AUTOSAR XML (schema 00046)
package /ComponentTypes
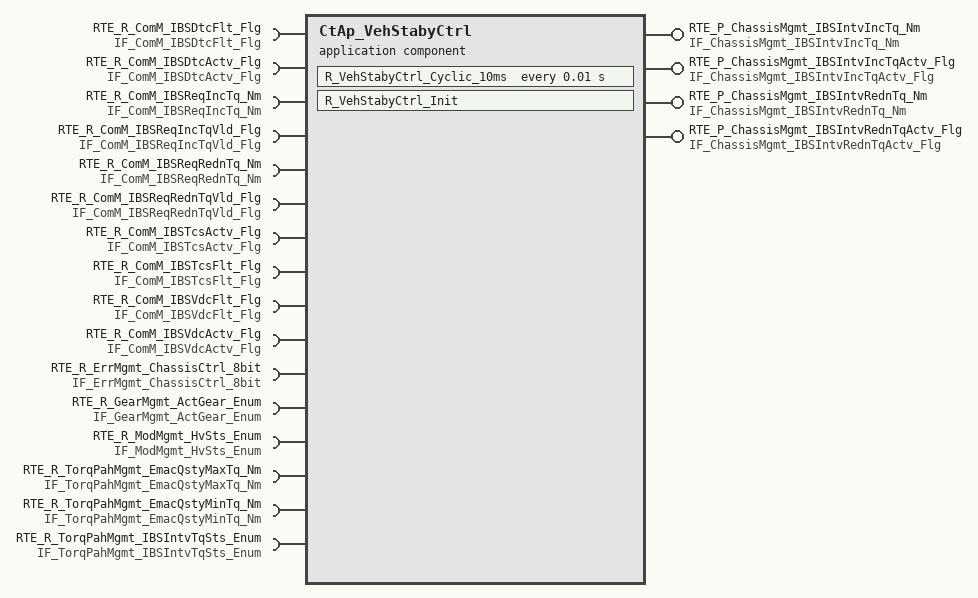
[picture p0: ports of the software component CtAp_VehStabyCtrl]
  application sw component type CtAp_VehStabyCtrl
    4 x provide port:
      RTE_P_ChassisMgmt_IBSIntvIncTq_Nm: nonqueued-sender-com-spec{data-element=tec_ChassisMgmt_IBSIntvIncTq_Nm, init-value=0}, provided-interface=IF_ChassisMgmt_IBSIntvIncTq_Nm
      RTE_P_ChassisMgmt_IBSIntvIncTqActv_Flg: nonqueued-sender-com-spec{data-element=tec_ChassisMgmt_IBSIntvIncTqActv_Flg, init-value=0}, provided-interface=IF_ChassisMgmt_IBSIntvIncTqActv_Flg
      RTE_P_ChassisMgmt_IBSIntvRednTq_Nm: nonqueued-sender-com-spec{data-element=tec_ChassisMgmt_IBSIntvRednTq_Nm, init-value=0}, provided-interface=IF_ChassisMgmt_IBSIntvRednTq_Nm
      RTE_P_ChassisMgmt_IBSIntvRednTqActv_Flg: nonqueued-sender-com-spec{data-element=tec_ChassisMgmt_IBSIntvRednTqActv_Flg, init-value=0}, provided-interface=IF_ChassisMgmt_IBSIntvRednTqActv_Flg
    16 x require port:
      RTE_R_ComM_IBSDtcFlt_Flg: nonqueued-receiver-com-spec{data-element=tec_ComM_IBSDtcFlt_Flg, filter=data-filter-type=ALWAYS, init-value=0}, required-interface=IF_ComM_IBSDtcFlt_Flg
      RTE_R_ComM_IBSDtcActv_Flg: nonqueued-receiver-com-spec{data-element=tec_ComM_IBSDtcActv_Flg, filter=data-filter-type=ALWAYS, init-value=0}, required-interface=IF_ComM_IBSDtcActv_Flg
      RTE_R_ComM_IBSReqIncTq_Nm: nonqueued-receiver-com-spec{data-element=tec_ComM_IBSReqIncTq_Nm, filter=data-filter-type=ALWAYS, init-value=0}, required-interface=IF_ComM_IBSReqIncTq_Nm
      RTE_R_ComM_IBSReqIncTqVld_Flg: nonqueued-receiver-com-spec{data-element=tec_ComM_IBSReqIncTqVld_Flg, filter=data-filter-type=ALWAYS, init-value=0}, required-interface=IF_ComM_IBSReqIncTqVld_Flg
      RTE_R_ComM_IBSReqRednTq_Nm: nonqueued-receiver-com-spec{data-element=tec_ComM_IBSReqRednTq_Nm, filter=data-filter-type=ALWAYS, init-value=0}, required-interface=IF_ComM_IBSReqRednTq_Nm
      RTE_R_ComM_IBSReqRednTqVld_Flg: nonqueued-receiver-com-spec{data-element=tec_ComM_IBSReqRednTqVld_Flg, filter=data-filter-type=ALWAYS, init-value=0}, required-interface=IF_ComM_IBSReqRednTqVld_Flg
      RTE_R_ComM_IBSTcsActv_Flg: nonqueued-receiver-com-spec{data-element=tec_ComM_IBSTcsActv_Flg, filter=data-filter-type=ALWAYS, init-value=0}, required-interface=IF_ComM_IBSTcsActv_Flg
      RTE_R_ComM_IBSTcsFlt_Flg: nonqueued-receiver-com-spec{data-element=tec_ComM_IBSTcsFlt_Flg, filter=data-filter-type=ALWAYS, init-value=0}, required-interface=IF_ComM_IBSTcsFlt_Flg
      RTE_R_ComM_IBSVdcFlt_Flg: nonqueued-receiver-com-spec{data-element=tec_ComM_IBSVdcFlt_Flg, filter=data-filter-type=ALWAYS, init-value=0}, required-interface=IF_ComM_IBSVdcFlt_Flg
      RTE_R_ComM_IBSVdcActv_Flg: nonqueued-receiver-com-spec{data-element=tec_ComM_IBSVdcActv_Flg, filter=data-filter-type=ALWAYS, init-value=0}, required-interface=IF_ComM_IBSVdcActv_Flg
      RTE_R_ErrMgmt_ChassisCtrl_8bit: nonqueued-receiver-com-spec{data-element=tec_ErrMgmt_ChassisCtrl_8bit, filter=data-filter-type=ALWAYS, init-value=0}, required-interface=IF_ErrMgmt_ChassisCtrl_8bit
      RTE_R_GearMgmt_ActGear_Enum: nonqueued-receiver-com-spec{data-element=tec_GearMgmt_ActGear_Enum, filter=data-filter-type=ALWAYS, init-value=0}, required-interface=IF_GearMgmt_ActGear_Enum
      RTE_R_ModMgmt_HvSts_Enum: nonqueued-receiver-com-spec{data-element=tec_ModMgmt_HvSts_Enum, filter=data-filter-type=ALWAYS, init-value=0}, required-interface=IF_ModMgmt_HvSts_Enum
      RTE_R_TorqPahMgmt_EmacQstyMaxTq_Nm: nonqueued-receiver-com-spec{data-element=tec_TorqPahMgmt_EmacQstyMaxTq_Nm, filter=data-filter-type=ALWAYS, init-value=0}, required-interface=IF_TorqPahMgmt_EmacQstyMaxTq_Nm
      RTE_R_TorqPahMgmt_EmacQstyMinTq_Nm: nonqueued-receiver-com-spec{data-element=tec_TorqPahMgmt_EmacQstyMinTq_Nm, filter=data-filter-type=ALWAYS, init-value=0}, required-interface=IF_TorqPahMgmt_EmacQstyMinTq_Nm
      RTE_R_TorqPahMgmt_IBSIntvTqSts_Enum: nonqueued-receiver-com-spec{data-element=tec_TorqPahMgmt_IBSIntvTqSts_Enum, filter=data-filter-type=ALWAYS, init-value=0}, required-interface=IF_TorqPahMgmt_IBSIntvTqSts_Enum
    behavior CtAp_VehStabyCtrl_InternalBehavior
      init event CtAp_VehStabyCtrl_InitEvent: start-on-event=R_VehStabyCtrl_Init
      timing event TMT_R_VehStabyCtrl_Cyclic_10ms: start-on-event=R_VehStabyCtrl_Cyclic_10ms, period=0.01
      runnable R_VehStabyCtrl_Init
      runnable R_VehStabyCtrl_Cyclic_10ms
        data-receive-point-by-arguments:
          16 x access:
            REC_RTE_R_ComM_IBSDtcActv_Flg_tec_ComM_IBSDtcActv_Flg: accessed-variable=RTE_R_ComM_IBSDtcActv_Flg.tec_ComM_IBSDtcActv_Flg
            REC_RTE_R_ComM_IBSDtcFlt_Flg_tec_ComM_IBSDtcFlt_Flg: accessed-variable=RTE_R_ComM_IBSDtcFlt_Flg.tec_ComM_IBSDtcFlt_Flg
            REC_RTE_R_ComM_IBSTcsActv_Flg_tec_ComM_IBSTcsActv_Flg: accessed-variable=RTE_R_ComM_IBSTcsActv_Flg.tec_ComM_IBSTcsActv_Flg
            REC_RTE_R_ComM_IBSTcsFlt_Flg_tec_ComM_IBSTcsFlt_Flg: accessed-variable=RTE_R_ComM_IBSTcsFlt_Flg.tec_ComM_IBSTcsFlt_Flg
            REC_RTE_R_ComM_IBSVdcActv_Flg_tec_ComM_IBSVdcActv_Flg: accessed-variable=RTE_R_ComM_IBSVdcActv_Flg.tec_ComM_IBSVdcActv_Flg
            REC_RTE_R_ComM_IBSVdcFlt_Flg_tec_ComM_IBSVdcFlt_Flg: accessed-variable=RTE_R_ComM_IBSVdcFlt_Flg.tec_ComM_IBSVdcFlt_Flg
            REC_RTE_R_Comm_IBSReqIncTqVld_Flg_tec_ComM_IBSReqIncTqVld_Flg: accessed-variable=RTE_R_ComM_IBSReqIncTqVld_Flg.tec_ComM_IBSReqIncTqVld_Flg
            REC_RTE_R_Comm_IBSReqIncTq_Nm_tec_ComM_IBSReqIncTq_Nm: accessed-variable=RTE_R_ComM_IBSReqIncTq_Nm.tec_ComM_IBSReqIncTq_Nm
            REC_RTE_R_Comm_IBSReqRednTqVld_Flg_tec_ComM_IBSReqRednTqVld_Flg: accessed-variable=RTE_R_ComM_IBSReqRednTqVld_Flg.tec_ComM_IBSReqRednTqVld_Flg
            REC_RTE_R_Comm_IBSReqRednTq_Nm_tec_ComM_IBSReqRednTq_Nm: accessed-variable=RTE_R_ComM_IBSReqRednTq_Nm.tec_ComM_IBSReqRednTq_Nm
            REC_RTE_R_ErrMgmt_ChassisCtrl_8bit_tec_ErrMgmt_ChassisCtrl_8bit: accessed-variable=RTE_R_ErrMgmt_ChassisCtrl_8bit.tec_ErrMgmt_ChassisCtrl_8bit
            REC_RTE_R_GearMgmt_ActGear_Enum_tec_GearMgmt_ActGear_Enum: accessed-variable=RTE_R_GearMgmt_ActGear_Enum.tec_GearMgmt_ActGear_Enum
            REC_RTE_R_ModMgmt_HvSts_Enum_tec_ModMgmt_HvSts_Enum: accessed-variable=RTE_R_ModMgmt_HvSts_Enum.tec_ModMgmt_HvSts_Enum
            REC_RTE_R_TorqPahMgmt_EmacQstyMaxTq_Nm_tec_TorqPahMgmt_EmacQstyMaxTq_Nm: accessed-variable=RTE_R_TorqPahMgmt_EmacQstyMaxTq_Nm.tec_TorqPahMgmt_EmacQstyMaxTq_Nm
            REC_RTE_R_TorqPahMgmt_EmacQstyMinTq_Nm_tec_TorqPahMgmt_EmacQstyMinTq_Nm: accessed-variable=RTE_R_TorqPahMgmt_EmacQstyMinTq_Nm.tec_TorqPahMgmt_EmacQstyMinTq_Nm
            REC_RTE_R_TorqPahMgmt_IBSIntvTqSts_Enum_tec_TorqPahMgmt_IBSIntvTqSts_Enum: accessed-variable=RTE_R_TorqPahMgmt_IBSIntvTqSts_Enum.tec_TorqPahMgmt_IBSIntvTqSts_Enum
        data-send-points:
          4 x access:
            SEND_RTE_P_ChassisMgmt_IBSIntvRednTqActv_Flg_tec_ChassisMgmt_IBSIntvRednTqActv_Flg: accessed-variable=RTE_P_ChassisMgmt_IBSIntvRednTqActv_Flg.tec_ChassisMgmt_IBSIntvRednTqActv_Flg
            SEND_RTE_P_ChassisMgmt_IBSIntvRednTq_Nm_tec_ChassisMgmt_IBSIntvRednTq_Nm: accessed-variable=RTE_P_ChassisMgmt_IBSIntvRednTq_Nm.tec_ChassisMgmt_IBSIntvRednTq_Nm
            SEND_RTE_P_ChassisMgmt_IBSIntvIncTqActv_Flg_tec_ChassisMgmt_IBSIntvIncTqActv_Flg: accessed-variable=RTE_P_ChassisMgmt_IBSIntvIncTqActv_Flg.tec_ChassisMgmt_IBSIntvIncTqActv_Flg
            SEND_RTE_P_ChassisMgmt_IBSIntvIncTq_Nm_tec_ChassisMgmt_IBSIntvIncTq_Nm: accessed-variable=RTE_P_ChassisMgmt_IBSIntvIncTq_Nm.tec_ChassisMgmt_IBSIntvIncTq_Nm
  swc implementation CtAp_VehStabyCtrl_Implementation: behavior=CtAp_VehStabyCtrl_InternalBehavior
    code-descriptors:
      code Default: artifact-descriptors=autosar-engineering-object=category=SWOBJ
